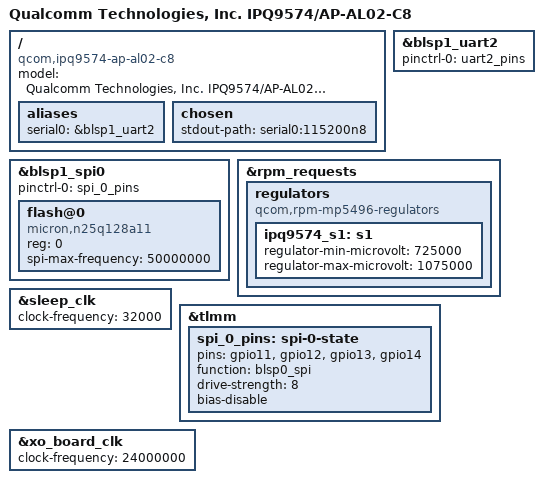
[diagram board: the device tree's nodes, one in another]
/dts-v1/;
#include "ipq9574.dtsi"
/ {
	model = "Qualcomm Technologies, Inc. IPQ9574/AP-AL02-C8";
	compatible = "qcom,ipq9574-ap-al02-c8", "qcom,ipq9574";
	aliases {
		serial0 = &blsp1_uart2;
	};
	chosen {
		stdout-path = "serial0:115200n8";
	};
};
&blsp1_spi0 {
	pinctrl-0 = <&spi_0_pins>;
	pinctrl-names = "default";
	status = "okay";
	flash@0 {
		compatible = "micron,n25q128a11", "jedec,spi-nor";
		reg = <0>;
		#address-cells = <1>;
		#size-cells = <1>;
		spi-max-frequency = <50000000>;
	};
};
&blsp1_uart2 {
	pinctrl-0 = <&uart2_pins>;
	pinctrl-names = "default";
	status = "okay";
};
&rpm_requests {
	regulators {
		compatible = "qcom,rpm-mp5496-regulators";
		ipq9574_s1: s1 {
			regulator-min-microvolt = <725000>;
			regulator-max-microvolt = <1075000>;
		};
	};
};
&sleep_clk {
	clock-frequency = <32000>;
};
&tlmm {
	spi_0_pins: spi-0-state {
		pins = "gpio11", "gpio12", "gpio13", "gpio14";
		function = "blsp0_spi";
		drive-strength = <8>;
		bias-disable;
	};
};
&xo_board_clk {
	clock-frequency = <24000000>;
};
